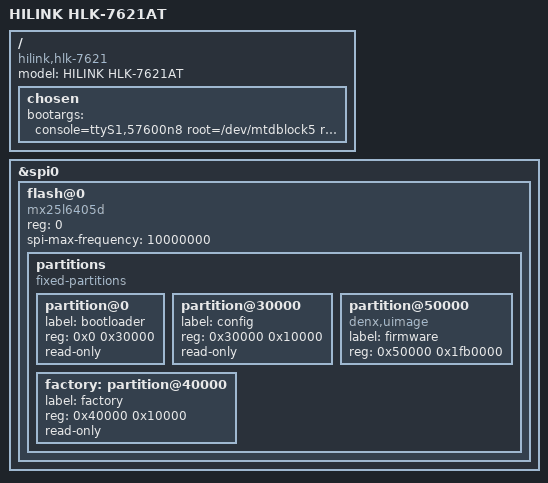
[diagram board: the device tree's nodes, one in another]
#include "mt7621.dtsi"

/ {
	compatible = "hilink,hlk-7621";
    model = "HILINK HLK-7621AT";

	chosen {
		bootargs = "console=ttyS1,57600n8 root=/dev/mtdblock5 rootfstype=squashfs,jffs2";
	};
};

&spi0 {
	status = "okay";

	flash@0 {
		compatible = "mx25l6405d","jedec,spi-nor","hilink,hlk-7621","w25q256";
		reg = <0>;
		spi-max-frequency = <10000000>;

		partitions {
			compatible = "fixed-partitions";
			#address-cells = <1>;
			#size-cells = <1>;

			partition@0 {
				label = "bootloader";
				reg = <0x0 0x30000>;
				read-only;
			};

			partition@30000 {
				label = "config";
				reg = <0x30000 0x10000>;
				read-only;
			};

			factory: partition@40000 {
				label = "factory";
				reg = <0x40000 0x10000>;
				read-only;
			};

			partition@50000 {
				compatible = "denx,uimage","hlk","hilink,hlk-7621";
				label = "firmware";
				reg = <0x50000 0x1fb0000>;
			};
		};
	};
};

